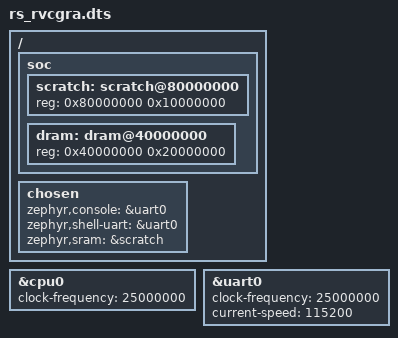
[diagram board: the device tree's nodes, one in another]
/* SPDX-License-Identifier: Apache-2.0 */

/dts-v1/;

#include <rs_rvcgra.dtsi>

/ {

	soc {
		scratch: scratch@80000000 {
			device_type = "memory";
			reg = < 0x80000000 0x10000000 >;
		};
	
		dram: dram@40000000 {
			device_type = "memory";
			reg = < 0x40000000 0x20000000 >;
		};
	
	};

	chosen {
		zephyr,console = &uart0;
		zephyr,shell-uart = &uart0;
		zephyr,sram = &scratch;
	};
};

&cpu0 {
	clock-frequency = <25000000>;
};

&uart0 {
	status = "okay";
	clock-frequency = <25000000>;
	current-speed = <115200>;
};
